# GD32A72_A74x register map
File version: 1.0
CPU: CM7 r2p1, little endian, MPU, FPU, DSP, 4 interrupt priority bits
Registers are 32-bit, read-write, reset 0x0 unless marked. A register's access mark holds for its fields unless they carry their own. Offsets are from the block's base; [hi:lo] are bit positions.

## CLTCFG — Client configuration
Base 0x40002400
0x00 SR_STAT0 — System Reset Status Register 0
  [0] ISO_STAT — PMU input isolation state
0x04 SR_STAT1 reset 0x1 — System Reset Status Register 1
  [0] RSTPIN_MOD — Specifies the reset pin mode
0x08 SR_STAT2 ro — System Reset Status Register 2
  [31] FFIOMOD — indicates the configuration of the fatal fault pins mode in option byte
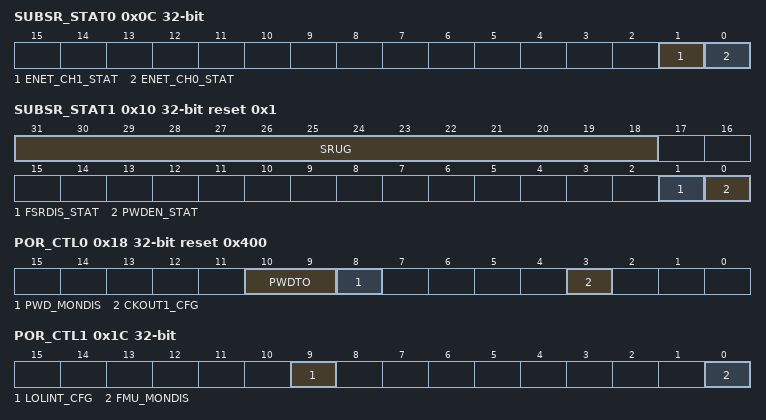
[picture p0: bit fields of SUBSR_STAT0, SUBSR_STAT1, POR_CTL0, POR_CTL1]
0x0C SUBSR_STAT0 — Subsystem Reset Status Register 0
  [1] ENET_CH1_STAT — Enet DMA channel 1 State
  [0] ENET_CH0_STAT — Enet DMA channel 0 State
0x10 SUBSR_STAT1 ro reset 0x1 — Subsystem Reset Status Register 1
  [31:18] SRUG — this field indicates the information of chip system reset escalation support for system reset sources as configured in option byte
  [1] FSRDIS_STAT — This bit indicates the final-step regulator automatic crossover from boot
  [0] PWDEN_STAT — This bit indicates the POR watchdog is enabled or not
0x14 SUBSR_STAT2 ro — Subsystem Reset Status Register 2
  [17:0] SRUG — this field indicates the information of chip system reset escalation support for system reset sources as configured in option byte
0x18 POR_CTL0 reset 0x400 — Power-on Reset Control Register 0
  [10:9] PWDTO — Configure timeout value of the POR watchdog
  [8] PWD_MONDIS — Disable the standby entry and exit monitor of the POR watchdog
  [3] CKOUT1_CFG — Clockout standby expose over system reset and subsystem reset
0x1C POR_CTL1 — Power-on Reset Control Register 1
  [9] LOLINT_CFG — Configuration of PLL loss of lock event
  [0] FMU_MONDIS — Disable FMU monitor
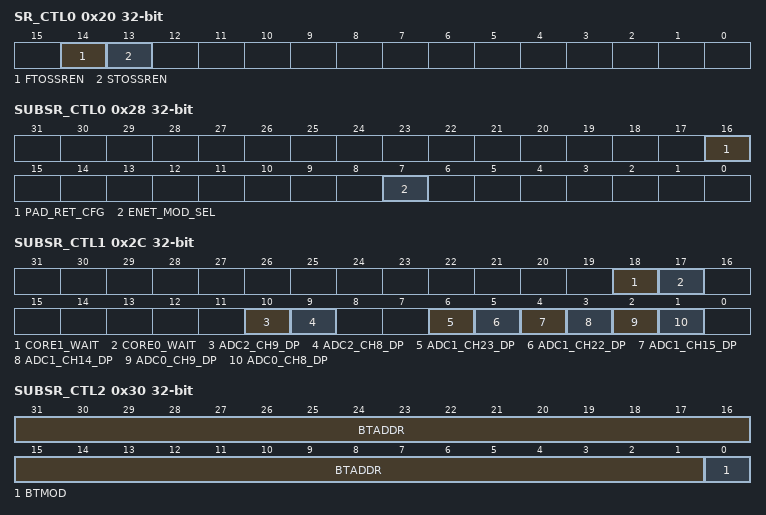
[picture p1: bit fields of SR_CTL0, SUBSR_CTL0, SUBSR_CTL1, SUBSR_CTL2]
0x20 SR_CTL0 — System Reset Control Register 0
  [14] FTOSSREN — Enable fast trace over subsystem reset
  [13] STOSSREN — Enable slow trace over subsystem reset
0x24 SR_CTL1 — System Reset Control Register 1
  [7] FRCFG — Configure the fault reaction state during selftest
0x28 SUBSR_CTL0 — Subsystem Reset Control Register 0
  [16] PAD_RET_CFG — configurate the io state in the standby mode
  [7] ENET_MOD_SEL — Ethernet mode selection
0x2C SUBSR_CTL1 — Subsystem Reset Control Register 1
  [18] CORE1_WAIT — Configuration for CM7 core 1 wait mode
  [17] CORE0_WAIT — Configuration for CM7 core 0 wait mode
  [10] ADC2_CH9_DP — Drive pin selection for ADC2 channel 9
  [9] ADC2_CH8_DP — Drive pin selection for ADC2 channel 8
  [6] ADC1_CH23_DP — Drive pin selection for ADC1 channel 23
  [5] ADC1_CH22_DP — Drive pin selection for ADC1 channel 22
  [4] ADC1_CH15_DP — Drive pin selection for ADC1 channel 15
  [3] ADC1_CH14_DP — Drive pin selection for ADC1 channel 14
  [2] ADC0_CH9_DP — Drive pin selection for ADC0 channel 9
  [1] ADC0_CH8_DP — Drive pin selection for ADC0 channel 8
0x30 SUBSR_CTL2 access per field — Subsystem Reset Control Register 2
  [31:1] BTADDR ro — SBAF application boot address after standby exit
  [0] BTMOD rw — Configure boot mode after exiting from standby
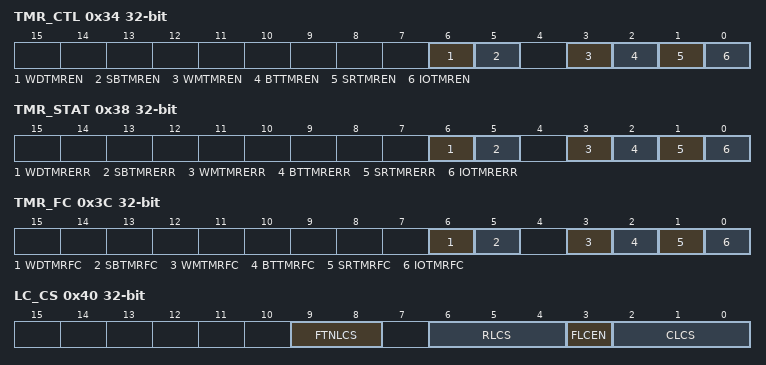
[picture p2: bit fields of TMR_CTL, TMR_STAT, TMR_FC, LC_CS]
0x34 TMR_CTL — Triple Modular Redundancy Control Register
  [6] WDTMREN — Watch dog TMR enable
  [5] SBTMREN — Standby mode TMR enable
  [3] WMTMREN — WM TMR enable
  [2] BTTMREN — Boot mode TMR enable
  [1] SRTMREN — System reset TMR enable
  [0] IOTMREN — GPIO TMR enable
0x38 TMR_STAT ro — Triple Modular Redundancy Status Register
  [6] WDTMRERR — Watch dog TMR error flag bit
  [5] SBTMRERR — Standby TMR error flag bit
  [3] WMTMRERR — WM TMR error flag bit
  [2] BTTMRERR — Boot mode TMR error flag bit
  [1] SRTMRERR — System reset TMR error flag bit
  [0] IOTMRERR — GPIO TMR error flag bit
0x3C TMR_FC wo — Triple Modular Redundancy Flag Clear Register
  [6] WDTMRFC — Clear bit for Watch dog TMR error flag
  [5] SBTMRFC — Clear bit for Standby TMR error flag
  [3] WMTMRFC — Clear bit for WM TMR error flag
  [2] BTTMRFC — Clear bit for Boot mode TMR error flag
  [1] SRTMRFC — Clear bit for System reset TMR error flag
  [0] IOTMRFC — Clear bit for GPIO TMR error flag
0x40 LC_CS access per field — Life Cycle Control and Status Register
  [9:8] FTNLCS rw — Force to next life cycle stage
  [6:4] RLCS ro — Real life cycle stage
  [3] FLCEN rw — Force LC
  [2:0] CLCS ro — Current life cycle stage
